# SAM9X60D1G_SOM device description
Architecture: ARM926EJ-S; Family: SAM9; Series: SAM9X6
Registers are 32-bit, read-write, no defined reset value unless marked. A register's access mark holds for its fields unless they carry their own. Offsets are from the block's base; [hi:lo] are bit positions; {n}, {i} and the like mark numbered series.

## UHPFS — USB Host Full-Speed Port
Instances: UHPHS_OHCI 0x00600000
0x00 UHPFS_HcRevision ro — OHCI Revision Number Register
  [7:0] REV — OHCI Revision Number
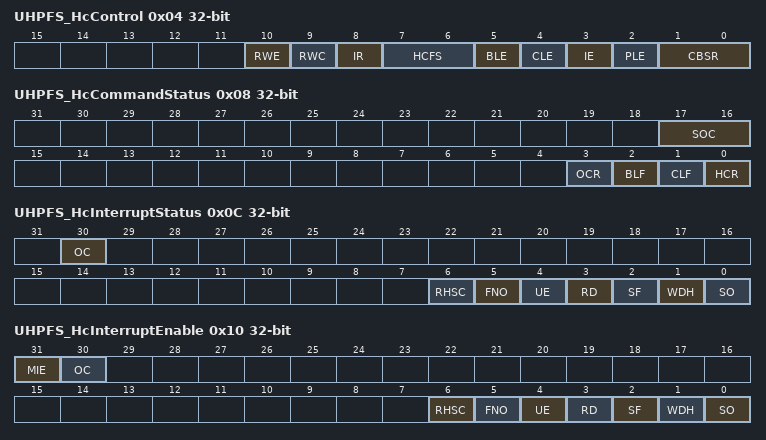
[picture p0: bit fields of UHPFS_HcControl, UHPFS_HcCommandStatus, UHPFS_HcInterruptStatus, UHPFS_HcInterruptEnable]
0x04 UHPFS_HcControl — HC Operating Mode Register
  [10] RWE — Remote Wakeup Enable
  [9] RWC — Remote Wakeup Connected
  [8] IR — Interrupt Routing
  [7:6] HCFS — Host Controller Functional State
  [5] BLE — Bulk List Enable
  [4] CLE — ControL List Enable
  [3] IE — Isochronous Enable
  [2] PLE — Periodic List Enable
  [1:0] CBSR — Control/Bulk Service Ratio
0x08 UHPFS_HcCommandStatus — HC Command and Status Register
  [17:16] SOC — Scheduling Overrun Count (read-only)
  [3] OCR — Ownership Change Request (read/write)
  [2] BLF — Bulk List Filled (read/write)
  [1] CLF — Control List Filled (read/write)
  [0] HCR — Host Controller Reset (read/write)
0x0C UHPFS_HcInterruptStatus — HC Interrupt and Status Register
  [30] OC — Ownership Change (read-only)
  [6] RHSC — Root Hub Status Change (read/write, write '1' to clear)
  [5] FNO — Frame Number Overflow (read/write, write '1' to clear)
  [4] UE — Unrecoverable Error (read/write, write '1' to clear)
  [3] RD — Resume Detected (read/write, write '1' to clear)
  [2] SF — Start of Frame (read/write, write '1' to clear)
  [1] WDH — Write Done Head (read/write, write '1' to clear)
  [0] SO — Scheduling Overrun (read/write, write '1' to clear)
0x10 UHPFS_HcInterruptEnable — HC Interrupt Enable Register
  [31] MIE — Master Interrupt Enable (read/write, write '1' to set)
  [30] OC — Ownership Change (read-only)
  [6] RHSC — Root Hub Status Change (read/write, write '1' to set)
  [5] FNO — Frame Number Overflow (read/write, write '1' to set)
  [4] UE — Unrecoverable Error (read/write, write '1' to set)
  [3] RD — Resume Detected (read/write, write '1' to set)
  [2] SF — Start of Frame (read/write, write '1' to set)
  [1] WDH — Write Done Head (read/write, write '1' to set)
  [0] SO — Scheduling Overrun (read/write, write '1' to set)
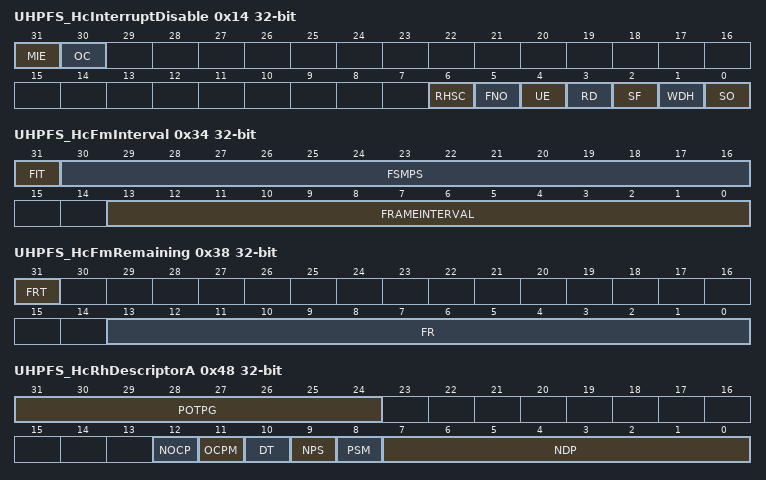
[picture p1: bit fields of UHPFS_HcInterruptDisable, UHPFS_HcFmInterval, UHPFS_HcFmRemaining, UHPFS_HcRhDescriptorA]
0x14 UHPFS_HcInterruptDisable — HC Interrupt Disable Register
  [31] MIE — Master Interrupt Enable (read/write)
  [30] OC — Ownership Change (read-only)
  [6] RHSC — Root Hub Status Change (read/write)
  [5] FNO — Frame Number Overflow (read/write)
  [4] UE — Unrecoverable Error (read/write)
  [3] RD — Resume Detected (read/write)
  [2] SF — Start of Frame (read/write)
  [1] WDH — Write Done Head (read/write)
  [0] SO — Scheduling Overrun (read/write)
0x18 UHPFS_HcHCCA — HC HCCA Address Register
  [31:8] HCCA — Physical Address of the Beginning of the HCCA
0x1C UHPFS_HcPeriodCurrentED — HC Current Periodic Register
  [31:4] PCED — Physical Address of the Current ED on the Periodic ED list
0x20 UHPFS_HcControlHeadED — HC Head Control Register
  [31:4] CHED — Physical Address of the Head ED on the Control ED list
0x24 UHPFS_HcControlCurrentED — HC Current Control Register
  [31:4] CCED — Physical Address of the Current ED on the Control ED List
0x28 UHPFS_HcBulkHeadED — HC Head Bulk Register
  [31:4] BHED — Physical Address of the Head ED on the Bulk ED List
0x2C UHPFS_HcBulkCurrentED — HC Current Bulk Register
  [31:4] BCED — Physical Address of the Current ED on the Bulk ED List
0x30 UHPFS_HcDoneHead — HC Head Done Register
  [31:4] DH — Physical Address of the Last TD that has added to the done queue
0x34 UHPFS_HcFmInterval — HC Frame Interval Register
  [31] FIT — Frame Interval Toggle
  [30:16] FSMPS — Largest Data Packet
  [13:0] FRAMEINTERVAL
0x38 UHPFS_HcFmRemaining — HC Frame Remaining Register
  [31] FRT — Frame Remaining Toggle
  [13:0] FR — Frame Remaining
0x3C UHPFS_HcFmNumber — HC Frame Number Register
  [15:0] FN — Frame Number
0x40 UHPFS_HcPeriodicStart — HC Periodic Start Register
  [13:0] PS — Periodic Start
0x44 UHPFS_HcLSThreshold — HC Low-Speed Threshold Register
  [13:0] LST — Low-Speed Threshold
0x48 UHPFS_HcRhDescriptorA — HC Root Hub A Register
  [31:24] POTPG — Power-On to Power-good Time (read/write)
  [12] NOCP — No Overcurrent Protection (read/write)
  [11] OCPM — Overcurrent Protection Mode (read/write)
  [10] DT — Device Type (read-only)
  [9] NPS — No Power Switching (read/write)
  [8] PSM — Power Switching Mode (read/write)
  [7:0] NDP — Number of Downstream Ports (read-only)
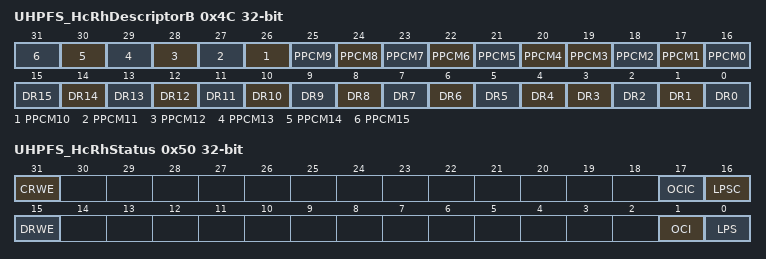
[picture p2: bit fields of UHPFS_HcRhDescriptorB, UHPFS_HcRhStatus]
0x4C UHPFS_HcRhDescriptorB — HC Root Hub B Register
  [n+16] PPCM{n} (n=4..15) — Port Power Control Mask
  [19] PPCM3 — Port Power Control Mask for Downstream Port 3
  [18] PPCM2 — Port Power Control Mask for Downstream Port 2
  [17] PPCM1 — Port Power Control Mask for Downstream Port 1
  [16] PPCM0 — Port Power Control Mask
  [n] DR{n} (n=4..15) — Device Removable
  [3] DR3 — Device Removable Bit for Downstream Port 3
  [2] DR2 — Device Removable Bit for Downstream Port 2
  [1] DR1 — Device Removable Bit for Downstream Port 1
  [0] DR0 — Device Removable
0x50 UHPFS_HcRhStatus — HC Root Hub Status Register
  [31] CRWE — Clear Remote Wakeup Enable (read/write)
  [17] OCIC — Overcurrent Indication Change (read/write)
  [16] LPSC — Local Power Status Change (read/write)
  [15] DRWE — Device Remote Wakeup Enable (read/write)
  [1] OCI — Overcurrent Indicator (read-only)
  [0] LPS — Local Power Status (read/write)
{0x54+4i} UHPFS_HcRhPortStatus[{i}] (i=0..2) — HC Port Status and Control Register (ndp = 0)
  [20] PRSC — Port Reset Status Change (read/write, write '1' to clear)
  [19] OCIC — Overcurrent Indicator Change (read/write)
  [18] PSSC — Port Suspend Status Change (read/write, write '1' to clear)
  [17] PESC — Port Enable Status Change (read/write, write '1' to clear)
  [16] CSC — Connect Status Change (read/write, write '1' to clear)
  [9] LSDA — Low-speed Device Attached/clear Port Power (read/write)
  [9] CPP — Low-speed Device Attached/clear Port Power (read/write)
  [8] PPS — Port Power Status/set Port Power (read/write)
  [8] SPP — Port Power Status/set Port Power (read/write)
  [4] PRS — Port Reset Status/set Port Reset (read/write)
  [4] SPR — Port Reset Status/set Port Reset (read/write)
  [3] POCI — Port Overcurrent Indicator/clear Suspend Status (read/write)
  [3] CSS — Port Overcurrent Indicator/clear Suspend Status (read/write)
  [2] PSS — Port Suspend Status/set Port Suspend (read/write)
  [2] SPS — Port Suspend Status/set Port Suspend (read/write)
  [1] PES — Port Enable Status/set Port Enable (read/write)
  [1] SPE — Port Enable Status/set Port Enable (read/write)
  [0] CCS — Port Current Connection Status/clear Port Enable (read/write)
  [0] CPE — Port Current Connection Status/clear Port Enable (read/write)
